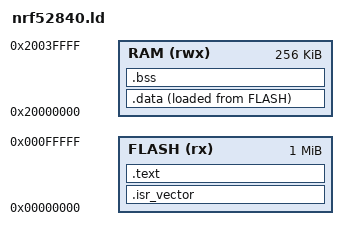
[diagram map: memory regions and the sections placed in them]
/* LabWired - PlatformIO + LabWired integration example
 * Minimal linker script for a no-framework nRF52840 (Cortex-M4) image.
 *
 * Flash base is 0x00000000 and RAM base 0x20000000, matching
 * configs/chips/nrf52840.yaml in the LabWired model. The LabWired ELF loader
 * places LOAD segments by physical address (LMA), so .data is kept resident in
 * flash and copied to RAM by the reset handler.
 */
MEMORY
{
  FLASH (rx)  : ORIGIN = 0x00000000, LENGTH = 1024K
  RAM   (rwx) : ORIGIN = 0x20000000, LENGTH = 256K
}

ENTRY(Reset_Handler)

_estack = ORIGIN(RAM) + LENGTH(RAM);

SECTIONS
{
  .isr_vector :
  {
    KEEP(*(.isr_vector))
  } > FLASH

  .text :
  {
    *(.text*)
    *(.rodata*)
    . = ALIGN(4);
  } > FLASH

  _sidata = LOADADDR(.data);

  .data :
  {
    . = ALIGN(4);
    _sdata = .;
    *(.data*)
    . = ALIGN(4);
    _edata = .;
  } > RAM AT > FLASH

  .bss :
  {
    . = ALIGN(4);
    _sbss = .;
    *(.bss*)
    *(COMMON)
    . = ALIGN(4);
    _ebss = .;
  } > RAM

  /DISCARD/ :
  {
    *(.ARM.exidx*)
    *(.note.gnu.build-id*)
  }
}
